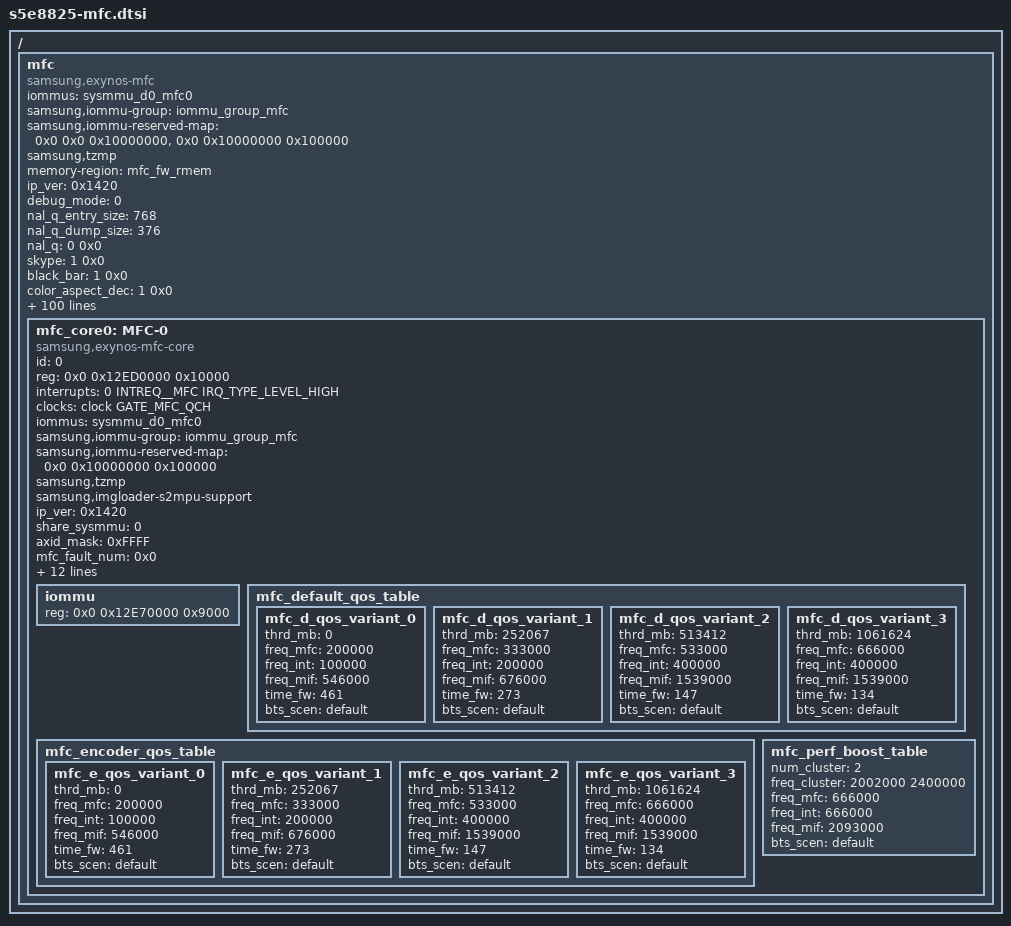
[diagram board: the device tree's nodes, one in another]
/*
 * SAMSUNG EXYNOS SoC mfc device tree source
 *
 * Copyright (c) 2018 Samsung Electronics Co., Ltd.
 *		http://www.samsung.com
 *
 * SAMSUNG EXYNOS SoC mfc device nodes are listed in this file.
 * EXYNOS based board files can include this file and provide
 * values for board specfic bindings.
 *
 * This program is free software; you can redistribute it and/or modify
 * it under the terms of the GNU General Public License version 2 as
 * published by the Free Software Foundation.
 */

#include <dt-bindings/clock/s5e8825.h>
#include <dt-bindings/interrupt-controller/s5e8825.h>

/ {
	mfc: mfc {
		/* Basic setting */
		compatible = "samsung,exynos-mfc";

		/* for vb2 device */
		iommus = <&sysmmu_d0_mfc0>;
		samsung,iommu-group = <&iommu_group_mfc>;
		samsung,iommu-reserved-map = <0x0 0x0 0x10000000>,
				<0x0 0x10000000 0x100000>;

		samsung,tzmp;

		/* for F/W buffer */
		memory-region = <&mfc_fw_rmem>;

		/* MFC version */
		ip_ver = <0x1420>;

		/* Debug mode (disable needs sysmmu,async-fault) */
		debug_mode = <0>;

		/* NAL-Q size */
		nal_q_entry_size = <768>;
		nal_q_dump_size = <376>;

		/* Features <on/off version> */
		nal_q = <0 0x0>;
		skype = <1 0x0>;
		black_bar = <1 0x0>;
		color_aspect_dec = <1 0x0>;
		static_info_dec = <1 0x0>;
		color_aspect_enc = <1 0x0>;
		static_info_enc = <1 0x180314>;
		hdr10_plus = <0 0x180709>;
		vp9_stride_align = <0 0x0>;
		sbwc_uncomp = <0 0x190702>;
		mem_clear = <1 0x0>;
		/* Support from v11.0 (except 11.2) */
		wait_fw_status = <1 0x190122>;
		wait_nalq_status = <0 0x191107>;
		/* DRM switch predict for cache flush */
		drm_switch_predict = <1 0x0>;
		/* Support SBWC per-frame control for encoder src */
		sbwc_enc_src_ctrl = <0 0x200110>;
		/* Use metadata interface */
		metadata_interface = <0 0x200910>;
		/* Support HDR10+ full data */
		hdr10_plus_full = <0 0x200910>;
		/* Average QP of encoder per frame */
		average_qp = <1 0x201030>;
		/* MV search mode */
		mv_search_mode = <1 0x201118>;
		/* Encoder IDR flag */
		enc_idr_flag = <1 0x210614>;
		/* Encoder min quality mode */
		min_quality_mode = <0 0x210705>;

		/* AV1 Decoder */
		support_av1_dec = <0>;
		/* Support AV1 Film Grain Feature */
		av1_film_grain = <0 0x200717>;

		/* Default 10bit format for decoding (1: P010, 0: 8+2) */
		P010_decoding = <1>;
		/* Dithering option for 8bit display device */
		dithering_enable = <0>;
		/* Decoder stride align (default: 16, AMD GPU: 256) */
		stride_align = <16>;
		/* Decoder stride calculation type (new: 1, old: 0) */
		stride_type = <0>;
		/* Encoder time stamp delta */
		enc_ts_delta = <1 0x211027>;

		/* Formats */
		support_10bit = <0>;
		support_422 = <0>;
		support_rgb = <0>;

		/* SBWC */
		support_sbwc = <1>;
		support_sbwcl = <0>;
		support_sbwcl40 = <0>;

		/* SBWC decoder max resolution */
		sbwc_dec_max_width = <1920>;
		sbwc_dec_max_height = <1088>;
		sbwc_dec_max_inst_num = <0>;
		sbwc_dec_max_framerate = <60>;
		sbwc_dec_hdr10_off = <0>;

		/* HDR10+ num max window */
		max_hdr_win = <0>;

		/* error type for sync_point display */
		/* (1: concealment display, 2: error display, 3: error no display) */
		display_err_type = <2>;

		/* FW base security ctrl */
		security_ctrl = <0>;
		/* output buffer Q framerate */
		display_framerate = <0>;

		/* Encoder default parameter: max number is 100 */
		enc_param_num = <19>;
		enc_param_addr = <0xF7B4 0xF7B8 0xF7B0 0xF798 0xFA2C
				0xF790 0xFA34 0xFA38 0xFA3C 0xFDD4
				0xFDDC 0xFB54 0xFB58 0xFBA8 0xFD40
				0xFD48 0xFD4C 0xFD50 0xFD80>;

		enc_param_val = <0x80 0x80 0x0 0x4000 0x3FD00
				0x0 0x0 0x2710 0x3E8 0x50D211
				0x0 0x3011 0x0 0x0 0x1D
				0xF4240 0x33003300 0x2 0x1>;

		/* BW <peak, read, write> : KB/UHD frame */
		bw_enc_h264		= <73114 48320 23788>;
		bw_enc_hevc		= <61440 39141 21211>;
		bw_enc_hevc_10bit	= <0 0 0>;
		bw_enc_vp8		= <73728 48361 24416>;
		bw_enc_vp9		= <0 0 0>;
		bw_enc_vp9_10bit	= <0 0 0>;
		bw_enc_mpeg4		= <0 0 0>;
		bw_dec_h264		= <70452 38216 23634>;
		bw_dec_hevc		= <63079 31942 20484>;
		bw_dec_hevc_10bit	= <0 0 0>;
		bw_dec_vp8		= <50074 26976 22324>;
		bw_dec_vp9		= <0 0 0>;
		bw_dec_vp9_10bit	= <0 0 0>;
		bw_dec_av1		= <0 0 0>;
		bw_dec_av1_10bit	= <0 0 0>;
		bw_dec_mpeg4		= <0 0 0>;

		/* BW <peak, read, write> : KB/UHD frame. For SBWC format */
		/* It is valid when only support_sbwc = <1> */
		sbwc_bw_enc_h264	= <0 0 0>;
		sbwc_bw_enc_hevc	= <0 0 0>;
		sbwc_bw_enc_hevc_10bit	= <0 0 0>;
		sbwc_bw_enc_vp8		= <0 0 0>;
		sbwc_bw_enc_vp9		= <0 0 0>;
		sbwc_bw_enc_vp9_10bit	= <0 0 0>;
		sbwc_bw_enc_mpeg4	= <0 0 0>;
		sbwc_bw_dec_h264	= <0 0 0>;
		sbwc_bw_dec_hevc	= <0 0 0>;
		sbwc_bw_dec_hevc_10bit	= <0 0 0>;
		sbwc_bw_dec_vp8		= <0 0 0>;
		sbwc_bw_dec_vp9		= <0 0 0>;
		sbwc_bw_dec_vp9_10bit	= <0 0 0>;
		sbwc_bw_dec_mpeg4	= <0 0 0>;

		/* QoS bitrate */
		num_mfc_freq = <8>;
		mfc_freqs = <133000 200000 266000 333000 400000 444000 533000 666000>;
		/* spec: H264(240M) VP8(80M) */
		max_Kbps = <245760 81920>;
		/* QoS weight (%) */
		dynamic_weight = <0>;
		qos_weight_h264_hevc = <100>;
		qos_weight_vp8_vp9 = <100>;
		qos_weight_av1 = <70>;
		qos_weight_other_codec = <25>;
		qos_weight_3plane = <80>;
		qos_weight_10bit = <75>;
		qos_weight_422 = <70>;
		qos_weight_bframe = <50>;
		qos_weight_num_of_ref = <60>;
		qos_weight_gpb = <50>;
		qos_weight_num_of_tile = <75>;
		qos_weight_super64_bframe = <60>;
		qos_weight_mbaff = <60>;

		/* core balance(%) for resource managing */
		core_balance = <100>;

		/* MFC IOVA threshold (MB) */
		iova_threshold = <1700>;

		/* need control for mfc idle clock */
		idle_clk_ctrl = <1>;

		/* QoS level for pm_qos dynamic control */
		qos_ctrl_level = <1>;

		/* QoS INT level for verification firmware (KHz) */
		int_freq_fw_verify = <266000>;

		/* mem-log buffer size */
		memlog_size = <0x80000>;
		memlog_sfr_size = <0x1000>;

		/* Encoder timing info disable */
		enc_timing_dis = <0>;

		/* Sub nodes for MFC core */
		#address-cells = <2>;
		#size-cells = <1>;
		ranges;

		/* MFC core device */
		mfc_core0: MFC-0 {
			/* Basic setting */
			compatible = "samsung,exynos-mfc-core";
			id = <0>;
			reg = <0x0 0x12ED0000 0x10000>;
			interrupts = <0 INTREQ__MFC IRQ_TYPE_LEVEL_HIGH>;
			clock-names = "aclk_mfc";
			clocks = <&clock GATE_MFC_QCH>;
			iommus = <&sysmmu_d0_mfc0>;
			samsung,iommu-group = <&iommu_group_mfc>;
			samsung,iommu-reserved-map = <0x0 0x10000000 0x100000>;

			samsung,tzmp;
			samsung,imgloader-s2mpu-support;
			/* MFC version */
			ip_ver = <0x1420>;

			/* Sysmmu check */
			share_sysmmu = <0>;
			axid_mask = <0xFFFF>;
			mfc_fault_num = <0x0>;
			trans_info_offset = <0x1004>;
			tsmux_axid = <0x1>;

			/* LLC (Last Level Cache) */
			llc = <0>;
			need_llc_flush = <0>;

			/* QoS */
			num_default_qos_steps = <4>;
			num_encoder_qos_steps = <4>;
			max_mb = <1352635>;
			max_hw_mb = <1224000>;
			mfc_freq_control = <1>;
			mo_control = <1>;
			bw_control = <1>;

			/* Sub nodes for sysmmu, hwfc and mmcache */
			#address-cells = <2>;
			#size-cells = <1>;
			ranges;

			/*start address, size */
			/* Device virtual address */
			#dma-address-cells = <1>;
			#dma-size-cells = <1>;
			dma-window = <0x0 0xC0000000>;

			iommu {
			        reg = <0x0 0x12E70000 0x9000>;
			};

			/* Default QoS table */
			mfc_default_qos_table {
				mfc_d_qos_variant_0 {
					thrd_mb = <0>;
					freq_mfc = <200000>;
					freq_int = <100000>;
					freq_mif = <546000>;
					time_fw = <461>;
					bts_scen = "default";
				};
				mfc_d_qos_variant_1 {
					thrd_mb = <252067>;
					freq_mfc = <333000>;
					freq_int = <200000>;
					freq_mif = <676000>;
					time_fw = <273>;
					bts_scen = "default";
				};
				mfc_d_qos_variant_2 {
					thrd_mb = <513412>;
					freq_mfc = <533000>;
					freq_int = <400000>;
					freq_mif = <1539000>;
					time_fw = <147>;
					bts_scen = "default";
				};
				mfc_d_qos_variant_3 {
					thrd_mb = <1061624>;
					freq_mfc = <666000>;
					freq_int = <400000>;
					freq_mif = <1539000>;
					time_fw = <134>;
					bts_scen = "default";
				};
			};

			/* Encoder only QoS table */
			mfc_encoder_qos_table {
				mfc_e_qos_variant_0 {
					thrd_mb = <0>;
					freq_mfc = <200000>;
					freq_int = <100000>;
					freq_mif = <546000>;
					time_fw = <461>;
					bts_scen = "default";
				};
				mfc_e_qos_variant_1 {
					thrd_mb = <252067>;
					freq_mfc = <333000>;
					freq_int = <200000>;
					freq_mif = <676000>;
					time_fw = <273>;
					bts_scen = "default";
				};
				mfc_e_qos_variant_2 {
					thrd_mb = <513412>;
					freq_mfc = <533000>;
					freq_int = <400000>;
					freq_mif = <1539000>;
					time_fw = <147>;
					bts_scen = "default";
				};
				mfc_e_qos_variant_3 {
					thrd_mb = <1061624>;
					freq_mfc = <666000>;
					freq_int = <400000>;
					freq_mif = <1539000>;
					time_fw = <134>;
					bts_scen = "default";
				};
			};

			/* QoS table for performance boost mode */
			mfc_perf_boost_table {
				num_cluster = <2>;
				freq_cluster = <2002000 2400000>;
				freq_mfc = <666000>;
				freq_int = <666000>;
				freq_mif = <2093000>;
				bts_scen = "default";
			};
		};
	};
};
